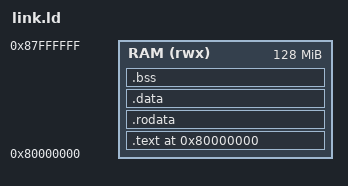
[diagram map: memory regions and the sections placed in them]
OUTPUT_ARCH( "riscv" )
ENTRY(_start)

MEMORY
{
  RAM (rwx) : ORIGIN = 0x80000000, LENGTH = 128M
}

SECTIONS
{
  . = 0x80000000;
  
  .text : {
    *(.text.init)
    *(.text)
    *(.text.*)
  } >RAM AT>RAM

  .rodata : {
    . = ALIGN(4);
    *(.rodata)
    *(.rodata.*)
  } >RAM AT>RAM

  .data : {
    . = ALIGN(4);
    *(.data)
    *(.data.*)
    *(.sdata)
    *(.sdata.*)
    . = ALIGN(4);
    *(.tohost)
  } >RAM AT>RAM

  .bss : {
    . = ALIGN(4);
    __bss_start = .;
    *(.bss)
    *(.bss.*)
    *(.sbss)
    *(.sbss.*)
    __bss_end = .;
  } >RAM AT>RAM
}
